VERSION ""

NS_ :

BS_:

BU_: DBC1
VAL_TABLE_ DBC1_Table 65535 "SNA" ;

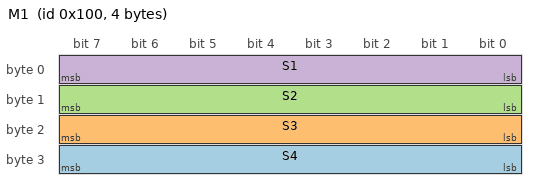
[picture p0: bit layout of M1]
BO_ 256 M1: 4 Vector__XXX
 SG_ S4 : 24|8@1- (1,0) [0|0] "" Vector__XXX
 SG_ S3 : 16|8@1- (1,0) [0|0] "" Vector__XXX
 SG_ S2 : 8|8@1- (1,0) [0|0] "" Vector__XXX
 SG_ S1 : 0|8@1- (1,0) [0|0] "" Vector__XXX

BA_DEF_  "BusType" STRING ;
BA_DEF_DEF_  "BusType" "CAN";

VAL_ 256 S1 65535 "SNA" ;
VAL_ 256 S2 65535 "SNA" ;
